# A31L22x register map
Vendor: VENDOR ABOV Semiconductor Co., Ltd.; Series: A31L22x; File version: 1.0
CPU: CM0+ r0p1, little endian, no MPU, no FPU, VTOR, 2 interrupt priority bits
Registers are 32-bit, read-write, reset 0x0 unless marked. A register's access mark holds for its fields unless they carry their own. Offsets are from the block's base; [hi:lo] are bit positions; {n}, {i} and the like mark numbered series; 'fields as' and 'values as' point back to an identical list.

## TS — Temperature Sensor
Base 0x40005F80
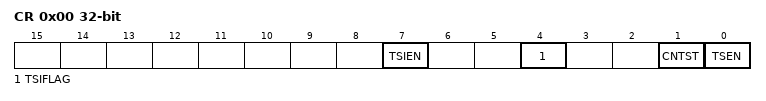
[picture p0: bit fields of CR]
0x00 CR — Temperature Sensor Control Register
  [7] TSIEN — Temperature Sensor Interrupt Enable
    0=Disable interrupt; 1=Enable interrupt
  [4] TSIFLAG — Temperature Sensor Interrupt flag
    0=No request occurred; 1=Request occurred. This bit is cleared to '0' when write '1'.
  [1] CNTST — Counting Start
    0=Stop counting; 1=Start (Counting start after 'reload data to TS_ICNT and clear TS_OUTDR'.)
  [0] TSEN — Temperature Sensor Enable
    0=Disable temperature sensor; 1=Enable temperature sensor
0x04 IDR reset 0xFFFF — Temperature Sensor Interval Data Register
  [15:0] IDATA — Temperature Sensor Interval Data
    0=Disable oversampling; 1=Enable oversampling
0x08 ICNTR ro reset 0xFFFF — Temperature Sensor Interval Counter Register
  [15:0] ICNT — Temperature Sensor Interval Counter
0x0C OUTDR ro — Temperature Sensor Output Data Register
  [23:0] OUTDATA — Temperature Sensor Output Data

## CMPn — Comparator n
Base 0x52000000
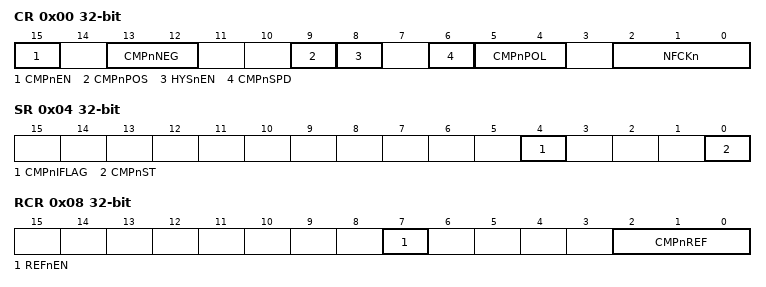
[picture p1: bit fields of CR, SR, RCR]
0x00 CR — Comparator n Control Register
  [15] CMPnEN — Comparator n Enable
    0=Disable comparator n operation; 1=Enable comparator n operation
  [13:12] CMPnNEG — Comparator n Negative Input Selection
    0=CPnN0 (Select external CPnN0 pin.); 1=CPnN1 (Select external CPnN1 pin.); 2=CPnN2 (Select external CPnN2 pin.); 3=IntRef (Select internal reference.)
  [9] CMPnPOS — Comparator n Positive Input Selection
    0=CPnP0 (Select external CPnP0 pin.); 1=CPnP1 (Select external CPnP1 pin. (CP1POS signal on comparator 0))
  [8] HYSnEN — Comparator n Hysteresis Enable
    0=Disable hysteresis function; 1=Enable hysteresis function
  [6] CMPnSPD — Comparator n Speed Selection
    0=Slow speed; 1=Fast speed
  [5:4] CMPnPOL — Comparator n Interrupt Polarity Selection
    0=No interrupt at any edge; 1=FallingEdge (Interrupt on falling edge); 2=RisingEdge (Interrupt on rising edge); 3=BothEdge (Interrupt on both of falling and rising edge)
  [2:0] NFCKn — Comparator n Noise Filter Sampling Clock Selection
    0=PCLK1; 1=PCLK2; 2=PCLK4; 3=PCLK8; 4=PCLK16; 5=PCLK32; 6=PCLK64
0x04 SR — Comparator n Status Register
  [4] CMPnIFLAG — Comparator n Interrupt Flag
    0=No request occurred; 1=Request occurred. This bit is cleared to '0' when write '1'.
  [0] CMPnST ro — Comparator n Output Status
    0=Low (Comparator n output is low.); 1=High (Comparator n output is high.)
0x08 RCR — Comparator n Reference Control Register
  [7] REFnEN — Comparator n Internal Reference Enable
    0=Disable internal reference; 1=Enable internal reference
  [2:0] CMPnREF — Comparator n Reference Voltage Level Selection
    {v}={v+2}over11VDD (Select reference voltage level {v}. NOTE) Reference voltage = (2+k)xVDD/11, k: 0 to 7) (v=0..7)

## CMP0 — Comparator 0
Base 0x40005600
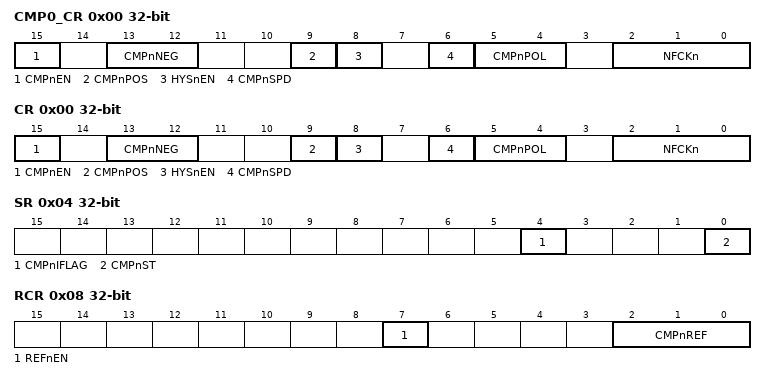
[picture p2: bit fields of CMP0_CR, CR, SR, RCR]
0x00 CMP0_CR (alternate view of CR) — Comparator 0 Control Register
  [15] CMPnEN — Comparator n Enable
    0=Disable comparator n operation; 1=Enable comparator n operation
  [13:12] CMPnNEG — Comparator n Negative Input Selection
    0=CPnN0 (Select external CPnN0 pin.); 1=CPnN1 (Select external CPnN1 pin.); 2=CPnN2 (Select external CPnN2 pin.); 3=IntRef (Select internal reference.)
  [9] CMPnPOS — Comparator n Positive Input Selection
    0=CPnP0 (Select external CPnP0 pin.); 1=CPnP1 (Select external CPnP1 pin. (CP1POS signal on comparator 0))
  [8] HYSnEN — Comparator n Hysteresis Enable
    0=Disable hysteresis function; 1=Enable hysteresis function
  [6] CMPnSPD — Comparator n Speed Selection
    0=Slow speed; 1=Fast speed
  [5:4] CMPnPOL — Comparator n Interrupt Polarity Selection
    0=No interrupt at any edge; 1=FallingEdge (Interrupt on falling edge); 2=RisingEdge (Interrupt on rising edge); 3=BothEdge (Interrupt on both of falling and rising edge)
  [2:0] NFCKn — Comparator n Noise Filter Sampling Clock Selection
    0=PCLK1; 1=PCLK2; 2=PCLK4; 3=PCLK8; 4=PCLK16; 5=PCLK32; 6=PCLK64
0x00 CR — Comparator n Control Register
  fields as CMP0_CR
0x04 SR — Comparator n Status Register
  [4] CMPnIFLAG — Comparator n Interrupt Flag
    0=No request occurred; 1=Request occurred. This bit is cleared to '0' when write '1'.
  [0] CMPnST ro — Comparator n Output Status
    0=Low (Comparator n output is low.); 1=High (Comparator n output is high.)
0x08 RCR — Comparator n Reference Control Register
  [7] REFnEN — Comparator n Internal Reference Enable
    0=Disable internal reference; 1=Enable internal reference
  [2:0] CMPnREF — Comparator n Reference Voltage Level Selection
    {v}={v+2}over11VDD (Select reference voltage level {v}. NOTE) Reference voltage = (2+k)xVDD/11, k: 0 to 7) (v=0..7)

## CMP1 — Comparator 1
Base 0x40005680
Registers as CMP0 (with CMP0 read as CMP1); these are added or differ:
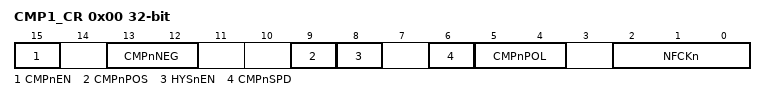
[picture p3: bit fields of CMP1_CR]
0x00 CMP1_CR (alternate view of CR) — Comparator 1 Control Register
  fields as CMP0.CMP0_CR
